AUTOSAR XML (schema 4-0-3)
package /driver_pkg/driver_swc
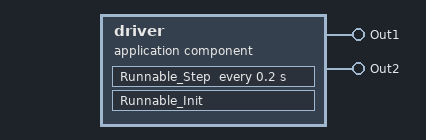
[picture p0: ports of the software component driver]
  application sw component type driver
    provide port Out1: nonqueued-sender-com-spec{data-element=Out1, init-value=0}, provided-interface=Out1
    provide port Out2: nonqueued-sender-com-spec{data-element=Out2, init-value=0}, provided-interface=Out2
    behavior driver: handle-termination-and-restart=NO-SUPPORT
      timing event Event_Runnable_Step: start-on-event=Runnable_Step, period=0.2
      runnable Runnable_Init
      runnable Runnable_Step
        data-write-access:
          access OUT_Out1_Out1: accessed-variable=Out1.Out1
          access OUT_Out2_Out2: accessed-variable=Out2.Out2
